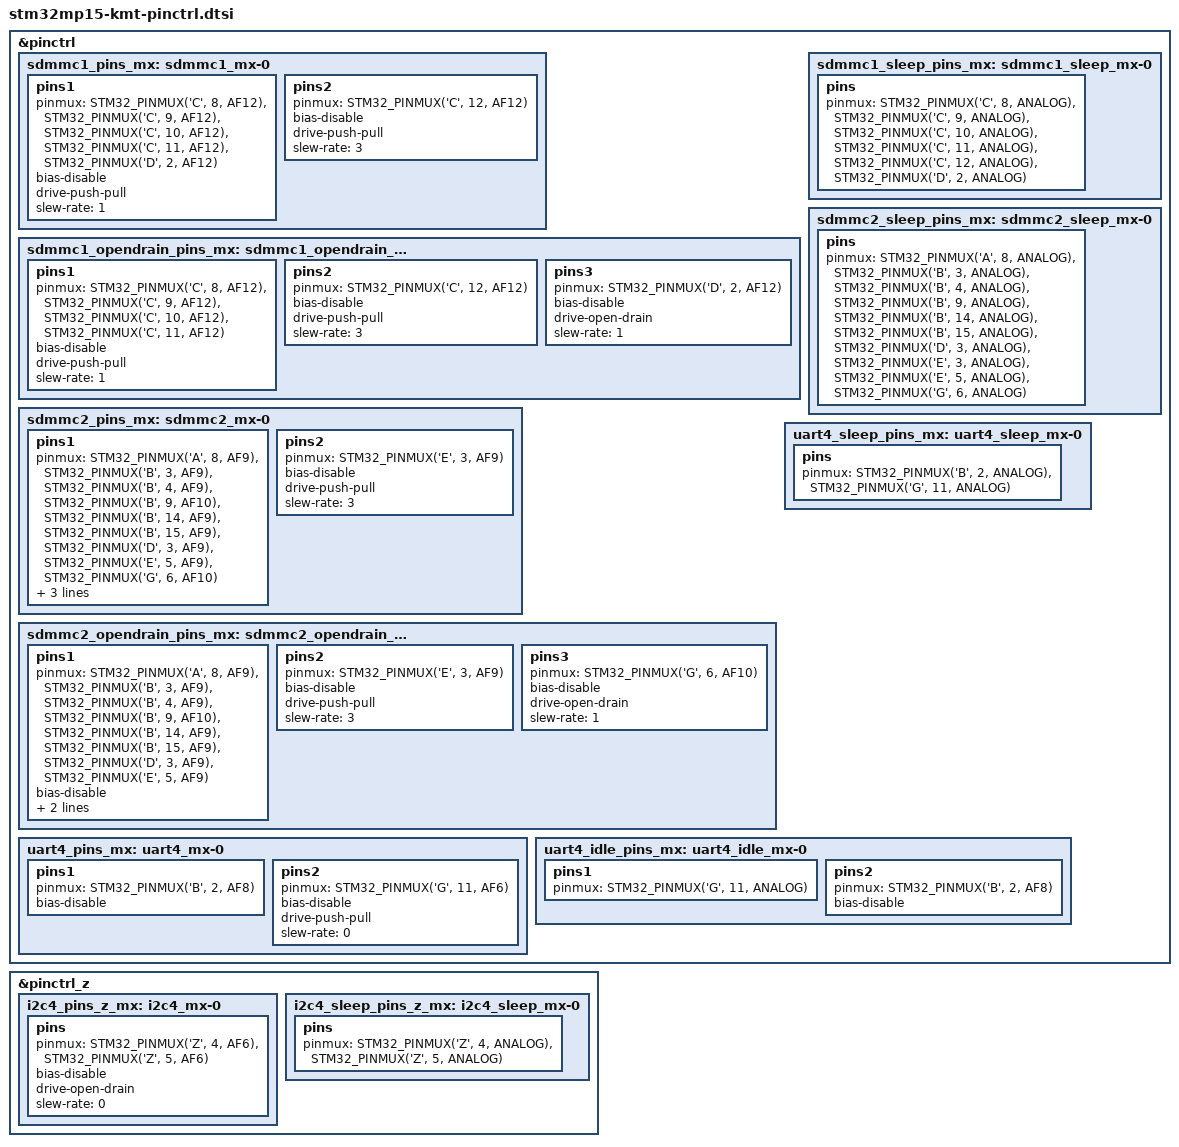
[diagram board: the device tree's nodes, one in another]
// SPDX-License-Identifier: (GPL-2.0+ OR BSD-3-Clause)
/*
 * Copyright (C) KienMinh Co,.Ltd 2021 - All Rights Reserved
 * Author: Phu Truong <phutruong@kienminh.net> for KienMinh Co,.Ltd.
 */
#include <dt-bindings/pinctrl/stm32-pinfunc.h>

&pinctrl {

	sdmmc1_pins_mx: sdmmc1_mx-0 {
		pins1 {
			pinmux = <STM32_PINMUX('C', 8, AF12)>, /* SDMMC1_D0 */
					 <STM32_PINMUX('C', 9, AF12)>, /* SDMMC1_D1 */
					 <STM32_PINMUX('C', 10, AF12)>, /* SDMMC1_D2 */
					 <STM32_PINMUX('C', 11, AF12)>, /* SDMMC1_D3 */
					 <STM32_PINMUX('D', 2, AF12)>; /* SDMMC1_CMD */
			bias-disable;
			drive-push-pull;
			slew-rate = <1>;
		};
		pins2 {
			pinmux = <STM32_PINMUX('C', 12, AF12)>; /* SDMMC1_CK */
			bias-disable;
			drive-push-pull;
			slew-rate = <3>;
		};
	};

	sdmmc1_opendrain_pins_mx: sdmmc1_opendrain_mx-0 {
		pins1 {
			pinmux = <STM32_PINMUX('C', 8, AF12)>, /* SDMMC1_D0 */
					 <STM32_PINMUX('C', 9, AF12)>, /* SDMMC1_D1 */
					 <STM32_PINMUX('C', 10, AF12)>, /* SDMMC1_D2 */
					 <STM32_PINMUX('C', 11, AF12)>; /* SDMMC1_D3 */
			bias-disable;
			drive-push-pull;
			slew-rate = <1>;
		};
		pins2 {
			pinmux = <STM32_PINMUX('C', 12, AF12)>; /* SDMMC1_CK */
			bias-disable;
			drive-push-pull;
			slew-rate = <3>;
		};
		pins3 {
			pinmux = <STM32_PINMUX('D', 2, AF12)>; /* SDMMC1_CMD */
			bias-disable;
			drive-open-drain;
			slew-rate = <1>;
		};
	};

	sdmmc1_sleep_pins_mx: sdmmc1_sleep_mx-0 {
		pins {
			pinmux = <STM32_PINMUX('C', 8, ANALOG)>, /* SDMMC1_D0 */
					 <STM32_PINMUX('C', 9, ANALOG)>, /* SDMMC1_D1 */
					 <STM32_PINMUX('C', 10, ANALOG)>, /* SDMMC1_D2 */
					 <STM32_PINMUX('C', 11, ANALOG)>, /* SDMMC1_D3 */
					 <STM32_PINMUX('C', 12, ANALOG)>, /* SDMMC1_CK */
					 <STM32_PINMUX('D', 2, ANALOG)>; /* SDMMC1_CMD */
		};
	};

	sdmmc2_pins_mx: sdmmc2_mx-0 {
		pins1 {
			pinmux = <STM32_PINMUX('A', 8, AF9)>, /* SDMMC2_D4 */
					 <STM32_PINMUX('B', 3, AF9)>, /* SDMMC2_D2 */
					 <STM32_PINMUX('B', 4, AF9)>, /* SDMMC2_D3 */
					 <STM32_PINMUX('B', 9, AF10)>, /* SDMMC2_D5 */
					 <STM32_PINMUX('B', 14, AF9)>, /* SDMMC2_D0 */
					 <STM32_PINMUX('B', 15, AF9)>, /* SDMMC2_D1 */
					 <STM32_PINMUX('D', 3, AF9)>, /* SDMMC2_D7 */
					 <STM32_PINMUX('E', 5, AF9)>, /* SDMMC2_D6 */
					 <STM32_PINMUX('G', 6, AF10)>; /* SDMMC2_CMD */
			bias-disable;
			drive-push-pull;
			slew-rate = <1>;
		};
		pins2 {
			pinmux = <STM32_PINMUX('E', 3, AF9)>; /* SDMMC2_CK */
			bias-disable;
			drive-push-pull;
			slew-rate = <3>;
		};
	};

	sdmmc2_opendrain_pins_mx: sdmmc2_opendrain_mx-0 {
		pins1 {
			pinmux = <STM32_PINMUX('A', 8, AF9)>, /* SDMMC2_D4 */
					 <STM32_PINMUX('B', 3, AF9)>, /* SDMMC2_D2 */
					 <STM32_PINMUX('B', 4, AF9)>, /* SDMMC2_D3 */
					 <STM32_PINMUX('B', 9, AF10)>, /* SDMMC2_D5 */
					 <STM32_PINMUX('B', 14, AF9)>, /* SDMMC2_D0 */
					 <STM32_PINMUX('B', 15, AF9)>, /* SDMMC2_D1 */
					 <STM32_PINMUX('D', 3, AF9)>, /* SDMMC2_D7 */
					 <STM32_PINMUX('E', 5, AF9)>; /* SDMMC2_D6 */
			bias-disable;
			drive-push-pull;
			slew-rate = <1>;
		};
		pins2 {
			pinmux = <STM32_PINMUX('E', 3, AF9)>; /* SDMMC2_CK */
			bias-disable;
			drive-push-pull;
			slew-rate = <3>;
		};
		pins3 {
			pinmux = <STM32_PINMUX('G', 6, AF10)>; /* SDMMC2_CMD */
			bias-disable;
			drive-open-drain;
			slew-rate = <1>;
		};
	};

	sdmmc2_sleep_pins_mx: sdmmc2_sleep_mx-0 {
		pins {
			pinmux = <STM32_PINMUX('A', 8, ANALOG)>, /* SDMMC2_D4 */
					 <STM32_PINMUX('B', 3, ANALOG)>, /* SDMMC2_D2 */
					 <STM32_PINMUX('B', 4, ANALOG)>, /* SDMMC2_D3 */
					 <STM32_PINMUX('B', 9, ANALOG)>, /* SDMMC2_D5 */
					 <STM32_PINMUX('B', 14, ANALOG)>, /* SDMMC2_D0 */
					 <STM32_PINMUX('B', 15, ANALOG)>, /* SDMMC2_D1 */
					 <STM32_PINMUX('D', 3, ANALOG)>, /* SDMMC2_D7 */
					 <STM32_PINMUX('E', 3, ANALOG)>, /* SDMMC2_CK */
					 <STM32_PINMUX('E', 5, ANALOG)>, /* SDMMC2_D6 */
					 <STM32_PINMUX('G', 6, ANALOG)>; /* SDMMC2_CMD */
		};
	};

	uart4_pins_mx: uart4_mx-0 {
		pins1 {
			pinmux = <STM32_PINMUX('B', 2, AF8)>; /* UART4_RX */
			bias-disable;
		};
		pins2 {
			pinmux = <STM32_PINMUX('G', 11, AF6)>; /* UART4_TX */
			bias-disable;
			drive-push-pull;
			slew-rate = <0>;
		};
	};

	uart4_sleep_pins_mx: uart4_sleep_mx-0 {
		pins {
			pinmux = <STM32_PINMUX('B', 2, ANALOG)>, /* UART4_RX */
					 <STM32_PINMUX('G', 11, ANALOG)>; /* UART4_TX */
		};
	};
	
	uart4_idle_pins_mx: uart4_idle_mx-0 {
		pins1 {
			pinmux = <STM32_PINMUX('G', 11, ANALOG)>; /* UART4_TX */
		};
		pins2 {
			pinmux = <STM32_PINMUX('B', 2, AF8)>; /* UART4_RX */
			bias-disable;
		};
	};
};

&pinctrl_z {

	i2c4_pins_z_mx: i2c4_mx-0 {
		pins {
			pinmux = <STM32_PINMUX('Z', 4, AF6)>, /* I2C4_SCL */
					 <STM32_PINMUX('Z', 5, AF6)>; /* I2C4_SDA */
			bias-disable;
			drive-open-drain;
			slew-rate = <0>;
		};
	};

	i2c4_sleep_pins_z_mx: i2c4_sleep_mx-0 {
		pins {
			pinmux = <STM32_PINMUX('Z', 4, ANALOG)>, /* I2C4_SCL */
					 <STM32_PINMUX('Z', 5, ANALOG)>; /* I2C4_SDA */
		};
	};
};
